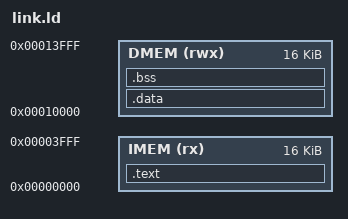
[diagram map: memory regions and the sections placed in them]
/* prog/link.ld */
ENTRY(_start)

MEMORY
{
    IMEM (rx)  : ORIGIN = 0x00000000, LENGTH = 16K
    DMEM (rwx) : ORIGIN = 0x00010000, LENGTH = 16K
}

SECTIONS
{
    .text : {
        *(.text.start)
        *(.text*)
        *(.rodata*)
    } > IMEM

    .data : {
        _data_start = .;
        *(.data*)
        _data_end = .;
    } > DMEM

    .bss : {
        _bss_start = .;
        *(.bss*)
        *(COMMON)
        _bss_end = .;
    } > DMEM

    _stack_top = ORIGIN(DMEM) + LENGTH(DMEM);
}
